AUTOSAR XML (schema 4-2-2)
package /AUTOLIV/SoftwareComponents/DioIf
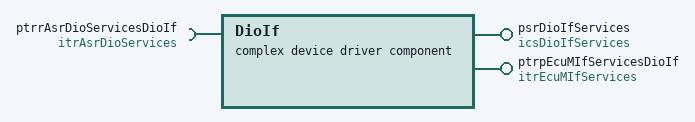
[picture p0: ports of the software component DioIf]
  complex device driver sw component type DioIf: category=MCAL_IO_Drivers
    provide port psrDioIfServices: provided-com-specs=[{operation=WriteChannel, queue-length=1}, {operation=ReadChannel, queue-length=1}], provided-interface=icsDioIfServices  # # Architecture Element ID ARCH_SW_DioIf_psrDioIfServices_DioIf_runReadChannel # Description - The DioIf_runReadChannel runnable shall be called in order to read the digital level of a pin. - A configurable array will hold the mapping to Dio channels(e.g. position 1 of configuration array is Dio Channel 7). - The runnable will select the Dio channel from the configuration array with the index from the {Mappend Channel Id} input parameter - The runnable will return the digital value of the selected uC pin via the {Digital Pin Level} output parameter # Data Flow ## Inputs - {Mapped Channel Id} ## Outptus - {Digital Pin Level} - Can be STD_HIGH, STD_LOW #Linked Runnable - DioIf_runReadChannel # Traceability -------------------------------------------------------------------------------------------------------------------------------------------- # Architecture Element ID ARCH_SW_DioIf_psrDioIfServices_DioIf_runWriteChannel # Description - The DioIf_runWriteChannel runnable shall be called in order to write the digital level of a pin. - A configurable array will hold the mapping to Dio channels(e.g. position 1 of configuration array is Dio Channel 7). - The runnable will select the Dio channel from the configuration array with the index from the {Mappend Channel Id} input parameter - The runnable will set the digital value from the {Digital Pin Level} input parameter for the the selected uC pin # Data Flow ## Inputs - {Mapped Channel Id} - {Digital Pin Level} - Can be STD_HIGH, STD_LOW #Linked Runnable - DioIf_runWriteChannel # Traceability
    provide port ptrpEcuMIfServicesDioIf: provided-interface=itrEcuMIfServices  # # Architecture Element ID ARCH_SW_DioIf_ptrpEcuMIfServicesDioIf_DioIf_Init # Description - The DioIf_Init runnable shall be called during the initialization in the EcuM_DefaultInitListOne runnable - The init function shall set the following pins: - EN_CS1 set to HIGH - EN_CS2 set to HIGH - EN_CS3 set to HIGH - EN_CS4 set to HIGH - EN_CS5 set to HIGH - EN_CS6 set to HIGH - Sleep_Off set to HIGH - ON_OFF_Power set to LOW - BOOST set to LOW - Wake_Cyclic_Power set to LOW # Data Flow #Linked Runnable - DioIf_Init # Traceability
    require port ptrrAsrDioServicesDioIf: required-interface=itrAsrDioServices  # # Architecture Element ID ARCH_SW_DioIf_ptrrAsrDioServicesDioIf_Dio_ReadChannel # Description - The Dio_ReadChannel runnable shall be called in the DioIf_runReadChannel runnable in order to read the digital level of a pin - The runnable will return the digital value of a uC pin via the {Digital Pin Level} output parameter for the selected pin on the {Channel Id} input parameter # Data Flow ## Inputs - {Channel Id} ## Outptus - {Digital Pin Level} - Can be STD_HIGH, STD_LOW #Linked Runnable - DioIf_runReadChannel # Traceability --------------------------------------------------------------------------------------------------------------------- # Architecture Element ID ARCH_SW_DioIf_ptrrAsrDioServices_Dio_WriteChannel_DioIf_runWriteChannel # Description - The Dio_WriteChannel runnable shall be called in the DioIf_runWriteChannel runnable in order to write a digital level to a pin - The runnable will set the digital value of a uC pin with the {Digital Pin Level} input parameter for the selected pin on the {Channel Id} input parameter # Data Flow ## Inputs - {Channel Id} - {Digital Pin Level} - Can be STD_HIGH, STD_LOW #Linked Runnable - DioIf_runWriteChannel # Traceability --------------------------------------------------------------------------------------------------------------------- # Architecture Element ID ARCH_SW_DioIf_ptrrAsrDioServices_Dio_WriteChannel_DioIf_Init # Description - The Dio_WriteChannel runnable shall be called in the DioIf_Init runnable in order to write a digital level to a pin - The runnable will set the digital value of a uC pin with the {Digital Pin Level} input parameter for the selected pin on the {Channel Id} input parameter # Data Flow ## Inputs - {Channel Id} - {Digital Pin Level} - Can be STD_HIGH, STD_LOW #Linked Runnable - DioIf_Init # Traceability
